# STM32WBA25xx register map
File version: 1.0
Registers are 32-bit, read-write, reset 0x0 unless marked. A register's access mark holds for its fields unless they carry their own. Offsets are from the block's base; [hi:lo] are bit positions; {n}, {i} and the like mark numbered series.

## SYSCFG — System configuration controller
Base 0x46000400
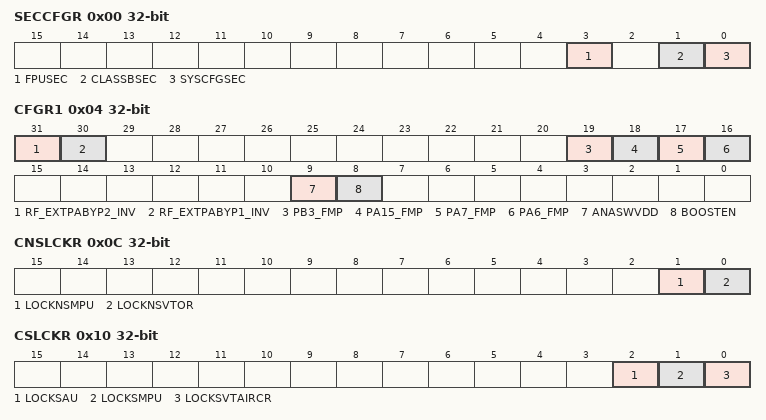
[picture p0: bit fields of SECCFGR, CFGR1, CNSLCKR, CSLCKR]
0x00 SECCFGR — SYSCFG secure configuration register
  [3] FPUSEC — FPU SYSCFG security enable
  [1] CLASSBSEC — ClassB SYSCFG security enable
  [0] SYSCFGSEC — SYSCFG clock control security enable
0x04 CFGR1 — SYSCFG configuration register 1
  [31] RF_EXTPABYP2_INV — signal RF_EXTPABYP2 inversion selection
  [30] RF_EXTPABYP1_INV — signal RF_EXTPABYP1 inversion selection
  [19] PB3_FMP — I2C PB3 Fast mode plus
  [18] PA15_FMP — I2C PA15 Fast mode plus
  [17] PA7_FMP — I2C PA7 Fast mode plus
  [16] PA6_FMP — I2C PA6 Fast mode plus
  [9] ANASWVDD — GPIO analog switch control voltage selection
  [8] BOOSTEN — I/O analog switch voltage booster enable
0x08 FPUIMR — SYSCFG FPU interrupt mask register
  [5:0] FPU_IE — All FPU interrupts enable
0x0C CNSLCKR — SYSCFG CPU non-secure lock register
  [1] LOCKNSMPU — Disable Non-Secure MPU registers writes by SW or debug agent
  [0] LOCKNSVTOR — Disable VTOR_NS register writes by SW or debug agent
0x10 CSLCKR — SYSCFG CPU secure lock register
  [2] LOCKSAU — Disable changes to SAU registers
  [1] LOCKSMPU — Disable changes to the secure MPU registers writes by SW or debug agent
  [0] LOCKSVTAIRCR — Disable changes to the secure vector table address, handling of system faults
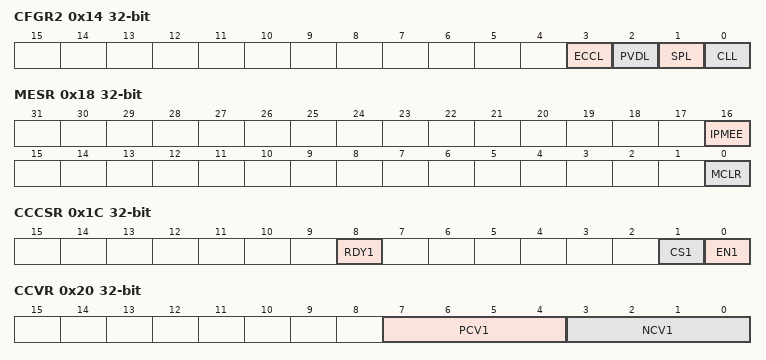
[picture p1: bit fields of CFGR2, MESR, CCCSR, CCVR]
0x14 CFGR2 — SYSCFG configuration register 2
  [3] ECCL — ECC Lock
  [2] PVDL — PVD Lock
  [1] SPL — SRAM Parity Lock
  [0] CLL — Core Lockup Lock
0x18 MESR — SYSCFG Memory Erase Status register
  [16] IPMEE — Status of End of Erase for ICache and PKA RAMs
  [0] MCLR — Status of Erase after Reset
0x1C CCCSR — SYSCFG Conpensation Cell Control&Status register
  [8] RDY1 — VDD compensation cell ready flag
  [1] CS1 — Code selection for VDD power rail
  [0] EN1 — Enable compensation cell for VDD power rail
0x20 CCVR — SYSCFG Conpensation Cell value register
  [7:4] PCV1 — PMOS compensation value for VDD Power Rail
  [3:0] NCV1 — NMOS compensation value for VDD Power Rail
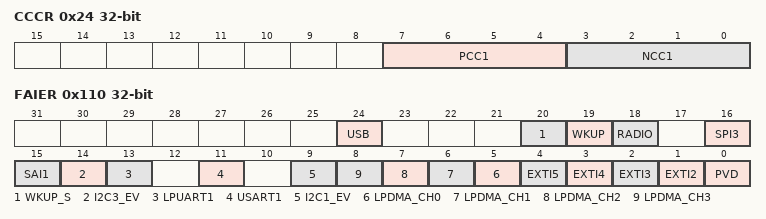
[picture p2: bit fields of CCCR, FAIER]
0x24 CCCR — SYSCFG Conpensation Cell Code register
  [7:4] PCC1 — PMOS compensation code for VDD Power Rail
  [3:0] NCC1 — NMOS compensation code for VDD Power Rail
0x2C RSSCMDR — SYSCFG RSS command mode register
  [15:0] RSSCMD — RSS command
0x110 FAIER — SYSCFG flash abort interrupt enable register
  [24] USB — enable USB interrupt to abort Flash operation
  [20] WKUP_S — enable PWR WKUP secure interrupt to abort Flash operation
  [19] WKUP — enable PWR WKUP interrupt to abort Flash operation
  [18] RADIO — enable RADIO interrupt to abort Flash operation
  [16] SPI3 — enable SPI3 interrupt to abort Flash operation
  [15] SAI1 — enable SAI1 interrupt to abort Flash operation
  [14] I2C3_EV — enable I2C3_EV interrupt to abort Flash operation
  [13] LPUART1 — enable LPUART1 interrupt to abort Flash operation
  [11] USART1 — enable USART1 interrupt to abort Flash operation
  [9] I2C1_EV — enable I2C1_EV interrupt to abort Flash operation
  [n+5] LPDMA_CH{n} (n=0..3) — enable LPDMA_CH{n} interrupt to abort Flash operation
  [n-1] EXTI{n} (n=2..5) — enable EXTI{n} interrupt to abort Flash operation
  [0] PVD — enable EXTI16 PVD interrupt to abort Flash operation

## EXTI — Asynch Interrupt/Event Controller (EXTI)
Base 0x46022000
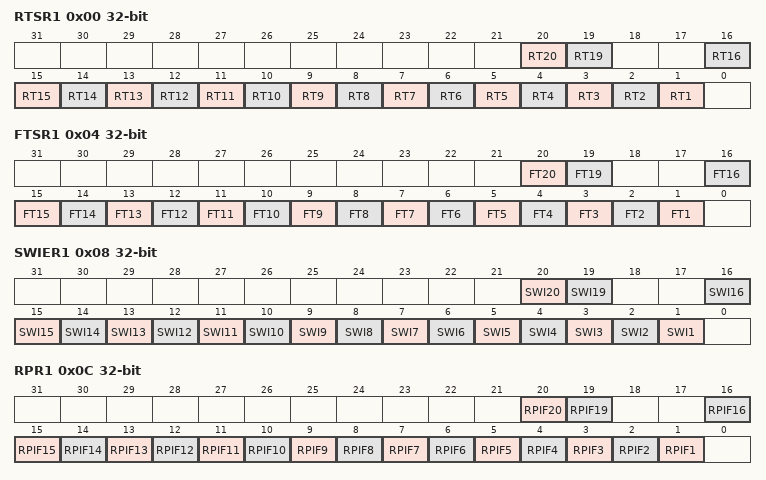
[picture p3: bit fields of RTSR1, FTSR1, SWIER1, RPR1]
0x00 RTSR1 — EXTI Rising Trigger Selection Register 1
  [20] RT20 — RT20 (Rising trigger event configuration bit of configurable event input x<sup>(1)</sup>)
  [19] RT19 — RT19 (Rising trigger event configuration bit of configurable event input x<sup>(1)</sup>)
  [n] RT{n} (n=1..16) — Rising trigger configuration for input line {n}
0x04 FTSR1 — EXTI Falling Trigger Selection Register 1
  [20] FT20 — FT20 (Falling trigger event configuration bit of configurable event input x<sup>(1)</sup>)
  [19] FT19 — FT19 (Falling trigger event configuration bit of configurable event input x<sup>(1)</sup>)
  [n] FT{n} (n=1..16) — Falling trigger configuration for input line {n}
0x08 SWIER1 — EXTI Software Interrupt event Register 1
  [20] SWI20 — SWI20 (Software interrupt on event x)
  [19] SWI19 — SWI19 (Software interrupt on event x)
  [n] SWI{n} (n=1..16) — Software Interrupt on line {n}
0x0C RPR1 — EXTI Rising Pending Register 1
  [20] RPIF20 — RPIF20 (configurable event inputs x rising edge pending bit)
  [19] RPIF19 — RPIF19 (configurable event inputs x rising edge pending bit)
  [n] RPIF{n} (n=1..16) — Rising Pending Interrupt Flag on line {n}
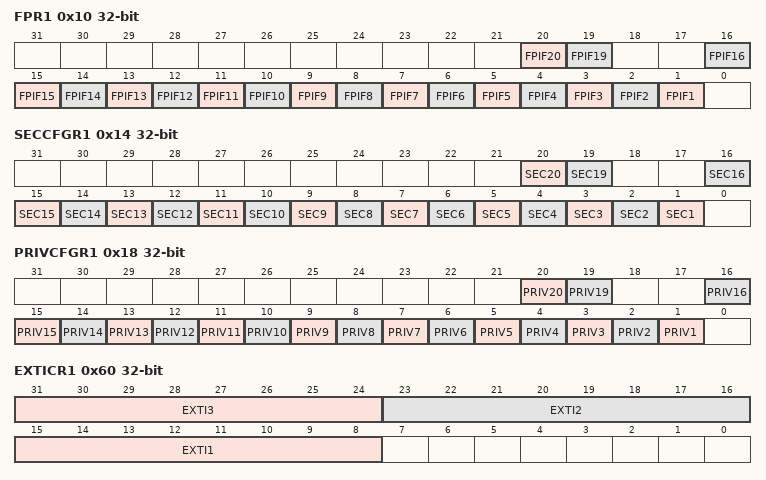
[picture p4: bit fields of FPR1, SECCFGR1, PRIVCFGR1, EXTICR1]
0x10 FPR1 — EXTI Falling Pending Register 1
  [20] FPIF20 — FPIF20 (configurable event inputs x falling edge pending bit)
  [19] FPIF19 — FPIF19 (configurable event inputs x falling edge pending bit)
  [n] FPIF{n} (n=1..16) — Falling Pending Interrupt Flag on line {n}
0x14 SECCFGR1 — EXTI Security Configuration Register 1
  [20] SEC20 — SEC20 (Security enable on event input x)
  [19] SEC19 — SEC19 (Security enable on event input x)
  [n] SEC{n} (n=1..16) — Security enable on line {n}
0x18 PRIVCFGR1 — EXTI Privilege Configuration Register 1
  [20] PRIV20 — PRIV20 (Security enable on event input x)
  [19] PRIV19 — PRIV19 (Security enable on event input x)
  [n] PRIV{n} (n=1..16) — Privilege enable on line {n}
0x60 EXTICR1 — EXIT External Interrupt Configuration Register, 0x60 -- 0x6C
  [31:24] EXTI3 — EXTI 3 configuration
  [23:16] EXTI2 — EXTI 2 configuration
  [15:8] EXTI1 — EXTI 1 configuration
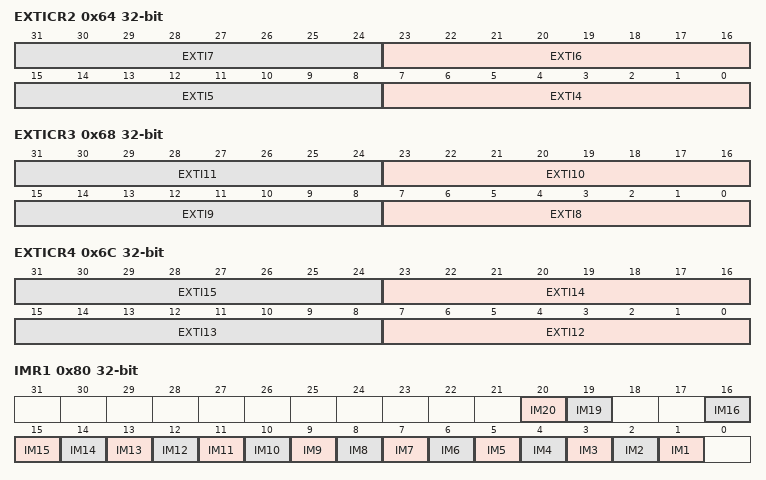
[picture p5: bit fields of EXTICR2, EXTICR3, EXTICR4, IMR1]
0x64 EXTICR2 — EXIT External Interrupt Configuration Register, 0x60 -- 0x6C
  [8n-25:8n-32] EXTI{n} (n=4..7) — EXTI {n} configuration
0x68 EXTICR3 — EXIT External Interrupt Configuration Register, 0x60 -- 0x6C
  [8n-57:8n-64] EXTI{n} (n=8..11) — EXTI {n} configuration
0x6C EXTICR4 — EXIT External Interrupt Configuration Register, 0x60 -- 0x6C
  [8n-89:8n-96] EXTI{n} (n=12..15) — EXTI {n} configuration
0x70 LOCKR — EXTI Lock Register
  [0] LOCK — Security and privilege configuration lock
0x80 IMR1 — EXTI Interrupt Mask Register 1
  [20] IM20 — IM20 (CPU wakeup with interrupt mask on event input x<sup>(1)</sup>)
  [19] IM19 — IM19 (CPU wakeup with interrupt mask on event input x<sup>(1)</sup>)
  [n] IM{n} (n=1..16) — Interrupt Mask on line {n}
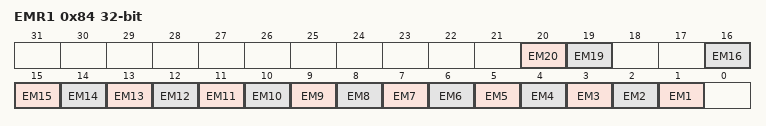
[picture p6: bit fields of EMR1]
0x84 EMR1 — EXTI Event Mask Register 1
  [20] EM20 — EM20 (CPU wakeup with event generation mask on event input x)
  [19] EM19 — EM19 (CPU wakeup with event generation mask on event input x)
  [n] EM{n} (n=1..16) — Event Mask on line {n}

## PTACONV
Base 0x48038000
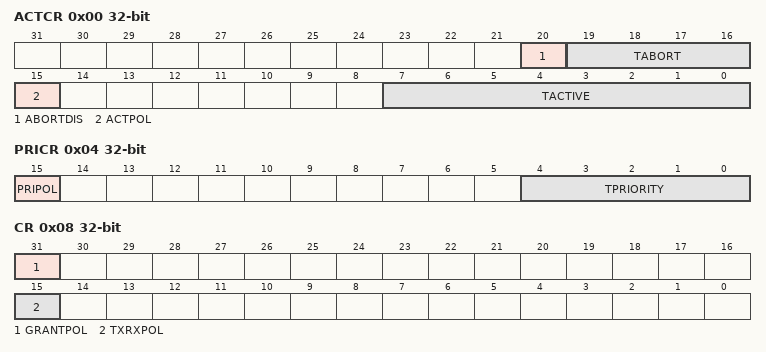
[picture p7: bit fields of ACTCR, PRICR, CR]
0x00 ACTCR — PTACONV active control register
  [20] ABORTDIS — Disable PTA_ACTIVE deny to abort an ongoing transmission
  [19:16] TABORT — PTA_ACTIVE delay to cease an ongoing transmission in us
  [15] ACTPOL — PTA_ACTIVE polarity
  [7:0] TACTIVE — PTA_ACTIVE setup time in us
0x04 PRICR — PTACONV priority control register
  [15] PRIPOL — Priority polarity
  [4:0] TPRIORITY — Priority valid time in us
0x08 CR — PTACONV control register
  [31] GRANTPOL — PTA_GRANT polarity
  [15] TXRXPOL — PTA_STATUS transmit and receive polarity

## DBGMCU — Debug MCU
Base 0xE0044000
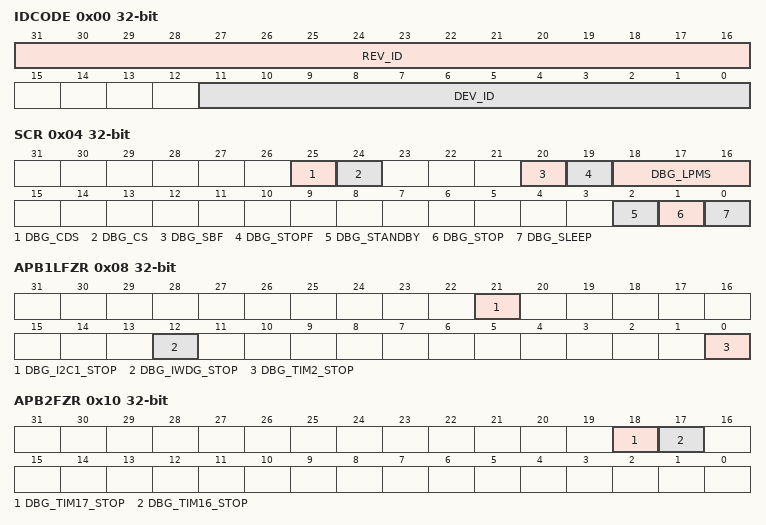
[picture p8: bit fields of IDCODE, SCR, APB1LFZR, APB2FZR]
0x00 IDCODE — MCU device ID code
  [31:16] REV_ID, [11:0] DEV_ID
0x04 SCR — Debug MCU status and configuration register
  [25] DBG_CDS
  [24] DBG_CS
  [20] DBG_SBF
  [19] DBG_STOPF
  [18:16] DBG_LPMS
  [2] DBG_STANDBY
  [1] DBG_STOP
  [0] DBG_SLEEP — DBG_SLEEP (Allows SRAM access in Sleep mode)
0x08 APB1LFZR — Debug MCU APB1 freeze register 1
  [21] DBG_I2C1_STOP, [12] DBG_IWDG_STOP, [0] DBG_TIM2_STOP
0x0C APB1HFZR — Debug MCU APB1 freeze register 2
  [5] DBG_LPTIM2_STOP
0x10 APB2FZR — Debug MCU APB2 freeze register
  [18] DBG_TIM17_STOP, [17] DBG_TIM16_STOP
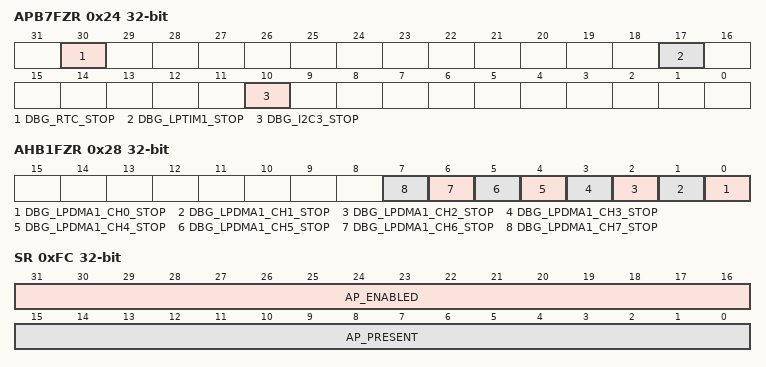
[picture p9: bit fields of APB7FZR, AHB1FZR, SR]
0x24 APB7FZR — Debug MCU APB7 freeze register
  [30] DBG_RTC_STOP, [17] DBG_LPTIM1_STOP, [10] DBG_I2C3_STOP
0x28 AHB1FZR — Debug MCU AHB1 freeze register
  [n] DBG_LPDMA1_CH{n}_STOP (n=0..7) — DBG_LPDMA1_CH{n}_STOP (LPDMA 1 channel {n} stop in CPU debug)
0xFC SR — Debug MCU status register
  [31:16] AP_ENABLED — AP_ENABLED[15:0] bits (Bit n identifies whether access port APn is open (can be accessed via the debug port) or locked (debug access to the APn is blocked, except for DBGMCU access))
  [15:0] AP_PRESENT — AP_PRESENT[15:0] bits (Bit n identifies whether access port APn is present in device)
0x100 DBG_AUTH_HOST — Debug MCU debug host authentication register
  [31:0] AUTH_KEY — AUTH_KEY[31:0] bits (Device authentication key)
0x104 DBG_AUTH_DEVICE — Debug MCU debug device authentication register
  [31:0] AUTH_ID — AUTH_ID[31:0] bits (Device specific ID)
